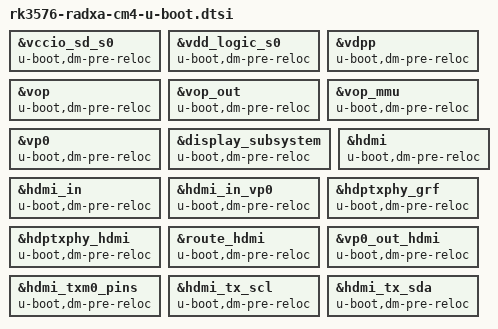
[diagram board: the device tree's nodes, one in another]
// SPDX-License-Identifier: (GPL-2.0+ OR MIT)
/*
 * Copyright (c) 2025 Rockchip Electronics Co., Ltd.
 * Copyright (c) 2025 Radxa Computer (Shenzhen) Co., Ltd.
*/

#include "rockchip/rk3576-u-boot.dtsi"

&vccio_sd_s0 {
	u-boot,dm-pre-reloc;
};

&vdd_logic_s0 {
	u-boot,dm-pre-reloc;
};

&vdpp {
	u-boot,dm-pre-reloc;
};

&vop {
	u-boot,dm-pre-reloc;
};

&vop_out {
	u-boot,dm-pre-reloc;
};

&vop_mmu {
	u-boot,dm-pre-reloc;
};

&vp0 {
	u-boot,dm-pre-reloc;
};

&display_subsystem {
	u-boot,dm-pre-reloc;
};

&hdmi {
	u-boot,dm-pre-reloc;
};

&hdmi_in {
	u-boot,dm-pre-reloc;
};

&hdmi_in_vp0 {
	u-boot,dm-pre-reloc;
};

&hdptxphy_grf {
	u-boot,dm-pre-reloc;
};

&hdptxphy_hdmi {
	u-boot,dm-pre-reloc;
};

&route_hdmi {
	u-boot,dm-pre-reloc;
};

&vp0_out_hdmi {
	u-boot,dm-pre-reloc;
};

&hdmi_txm0_pins {
	u-boot,dm-pre-reloc;
};

&hdmi_tx_scl {
	u-boot,dm-pre-reloc;
};

&hdmi_tx_sda {
	u-boot,dm-pre-reloc;
};
